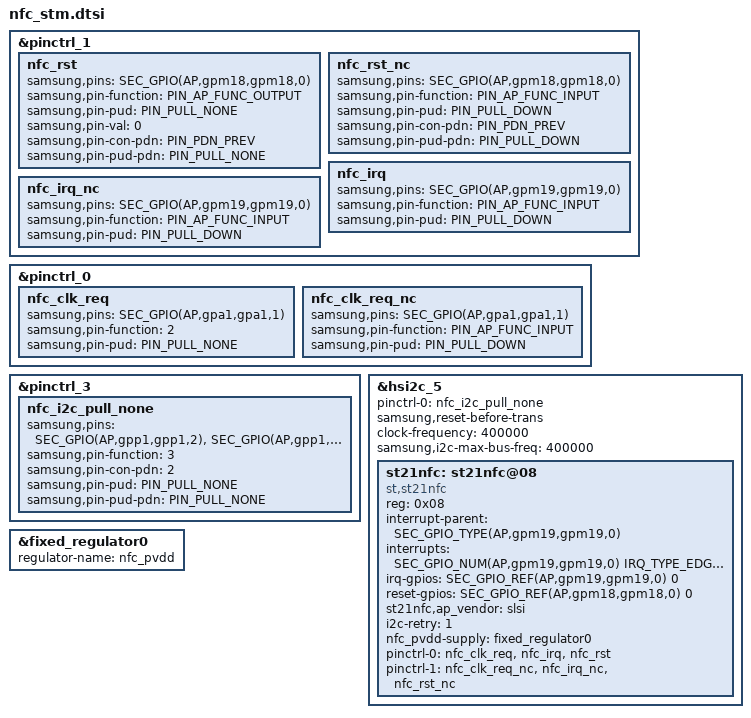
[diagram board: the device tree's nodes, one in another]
/*
 * This program is free software; you can redistribute it and/or modify
 * it under the terms of the GNU General Public License version 2 and
 * only version 2 as published by the Free Software Foundation.
 *
 * This program is distributed in the hope that it will be useful,
 * but WITHOUT ANY WARRANTY; without even the implied warranty of
 * MERCHANTABILITY or FITNESS FOR A PARTICULAR PURPOSE.  See the
 * GNU General Public License for more details.
 */

/* 
 * #define PIN_AP_FUNC_INPUT		0x0
 * #define PIN_AP_FUNC_OUTPUT		0x1
 * #define PIN_AP_FUNC_OUTPUT_HIGH	0x1
 * #define PIN_AP_FUNC_OUTPUT_LOW	0x1
 * #define PIN_AP_FUNC_INPUT_WAKEUP	0xf

 * arch/arm64/boot/dts/samsung/exynos_gpio_config_macros.dtsi
 * #define PIN_PDN_OUT0		0
 * #define PIN_PDN_OUT1		1
 * #define PIN_PDN_INPUT	2
 * #define PIN_PDN_PREV		3
 */

#ifndef PIN_PDN_PREV
#define PIN_PDN_PREV	3
#endif

&pinctrl_1 {
	nfc_rst: nfc_rst {
		samsung,pins = SEC_GPIO(AP,gpm18,gpm18,0);
		samsung,pin-function = <PIN_AP_FUNC_OUTPUT>;
		samsung,pin-pud = <PIN_PULL_NONE>;
		samsung,pin-val = <0>;
		samsung,pin-con-pdn = <PIN_PDN_PREV>;
		samsung,pin-pud-pdn = <PIN_PULL_NONE>;
	};
	nfc_rst_nc: nfc_rst_nc {
		samsung,pins = SEC_GPIO(AP,gpm18,gpm18,0);
		samsung,pin-function = <PIN_AP_FUNC_INPUT>;
		samsung,pin-pud = <PIN_PULL_DOWN>;
		samsung,pin-con-pdn = <PIN_PDN_PREV>;
		samsung,pin-pud-pdn = <PIN_PULL_DOWN>;
	};
};
&pinctrl_0 {
	nfc_clk_req: nfc_clk_req {
		samsung,pins = SEC_GPIO(AP,gpa1,gpa1,1);
		samsung,pin-function = <2>;
		samsung,pin-pud = <PIN_PULL_NONE>;
	};
	nfc_clk_req_nc: nfc_clk_req_nc {
		samsung,pins = SEC_GPIO(AP,gpa1,gpa1,1);
		samsung,pin-function = <PIN_AP_FUNC_INPUT>;
		samsung,pin-pud = <PIN_PULL_DOWN>;
	};
};

&pinctrl_1 {
	nfc_irq: nfc_irq {
		samsung,pins = SEC_GPIO(AP,gpm19,gpm19,0);
		samsung,pin-function = <PIN_AP_FUNC_INPUT>;
		samsung,pin-pud = <PIN_PULL_DOWN>;
	};
	nfc_irq_nc: nfc_irq_nc {
		samsung,pins = SEC_GPIO(AP,gpm19,gpm19,0);
		samsung,pin-function = <PIN_AP_FUNC_INPUT>;
		samsung,pin-pud = <PIN_PULL_DOWN>;
	};
};

#if 0
&${xclkout_parent} {
	nfc_xclkout: nfc_xclkout {
		samsung,pins = SEC_GPIO(${xclkout_gpio});
		samsung,pin-function = <2>;
		samsung,pin-pud = <PIN_PULL_NONE>;
	};
};
#endif

&pinctrl_3 {
	nfc_i2c_pull_none: nfc_i2c_pull_none {
		samsung,pins = SEC_GPIO(AP,gpp1,gpp1,2), SEC_GPIO(AP,gpp1,gpp1,3);
		samsung,pin-function = <3>;
		samsung,pin-con-pdn = <2>; /* PIN_PDN_INPUT */
		samsung,pin-pud = <PIN_PULL_NONE>;
		samsung,pin-pud-pdn = <PIN_PULL_NONE>;
	};

#if 0
	nfc_i2c_no_change: nfc_i2c_no_change {
		samsung,pins = SEC_GPIO(AP,gpp1,gpp1,2), SEC_GPIO(AP,gpp1,gpp1,3);
		samsung,pin-function = <3>;
		samsung,pin-con-pdn = <2>; /* PIN_PDN_INPUT */
	};
	nfc_i2c_pull_up: nfc_i2c_pull_up {
		samsung,pins = SEC_GPIO(AP,gpp1,gpp1,2), SEC_GPIO(AP,gpp1,gpp1,3);
		samsung,pin-function = <3>;
		samsung,pin-con-pdn = <2>; /* PIN_PDN_INPUT */
		samsung,pin-pud = <PIN_PULL_UP>;
		samsung,pin-pud-pdn = <PIN_PULL_UP>;
	};
#endif
};

#if 0
&${nfc_check_parent} {
	nfc_check: nfc_check {
		samsung,pins = SEC_GPIO(${nfc_check});
		samsung,pin-function = <PIN_AP_FUNC_INPUT>;
		samsung,pin-pud = <PIN_PULL_NONE>;
		samsung,pin-con-pdn = <PIN_PDN_PREV>;
		samsung,pin-pud-pdn = <PIN_PULL_NONE>;
	};
};
#endif

&hsi2c_5 {
	status = "ok";
	/delete-property/ pinctrl-names;
	/delete-property/ pinctrl-0;
#if 0
	pinctrl-names = "default", "i2c_pull_up";
	pinctrl-0 = <&nfc_i2c_no_change>;
	pinctrl-1 = <&nfc_i2c_pull_up>;
#else
	pinctrl-names = "default";
	pinctrl-0 = <&nfc_i2c_pull_none>;
#endif
	samsung,reset-before-trans;
	clock-frequency = <400000>; /* for HWI2C */
	samsung,i2c-max-bus-freq = <400000>; /* for Normal HW I2C */
	st21nfc: st21nfc@08 {
		compatible = "st,st21nfc";
		reg = <0x08>;
		interrupt-parent = <SEC_GPIO_TYPE(AP,gpm19,gpm19,0)>;
		interrupts = <SEC_GPIO_NUM(AP,gpm19,gpm19,0) IRQ_TYPE_EDGE_RISING
			SEC_GPIO_NUM(AP,gpm19,gpm19,0) 0>;
		irq-gpios = <SEC_GPIO_REF(AP,gpm19,gpm19,0) 0>;
		reset-gpios = <SEC_GPIO_REF(AP,gpm18,gpm18,0) 0>;
#if 0
		clkreq-gpios = <SEC_GPIO_REF(AP,gpa1,gpa1,1) 0>;
#endif
		st21nfc,ap_vendor = "slsi";
		i2c-retry = <1>;
#if 0
		st21nfc,nfc-det-gpio = <SEC_GPIO_REF(${nfc_check}) 0>;
#endif
#if 0
		st21nfc,late_pvdd_en;
#endif
#if 1
		nfc_pvdd-supply = <&fixed_regulator0>;
#endif

#if 0
		st21nfc,clk_req_wake;
#endif
#if 0
		st21nfc,irq_all_trigger;
#endif
#if 0
		st,clk_pinctrl;
		clocks = <&clock OSC_NFC>;
		clock-names = "nfc_ref_clk";
#endif

		pinctrl-names = "default", "nfc_nc";
/* default */
		pinctrl-0 = <&nfc_clk_req &nfc_irq &nfc_rst
#if 0
			&nfc_xclkout
#endif
#if 0
			&nfc_check
#endif
			>;
/* nfc_nc */
		pinctrl-1 = <&nfc_clk_req_nc &nfc_irq_nc &nfc_rst_nc>;
	};
};

&fixed_regulator0 {
	regulator-name = "nfc_pvdd";
};

#if 0

#if 0
&${ese_check_parent} {
	ese_check_default: ese_check_default {
		GPIO_CONFIG_PUD_DRV(${ese_check}, FUNC_INPUT, PULL_NONE, DRV_LV3);
		samsung,pin-con-pdn = <2>; /* PIN_PDN_INPUT */
		samsung,pin-pud-pdn = <PIN_PULL_NONE>;
	};
};
#endif

&${ese_ap_ese_rst_parent} {
	ese_ap_ese_rst_default: ese_ap_ese_rst_default {
		GPIO_CONFIG_PUD_DRV(${ese_ap_ese_rst}, FUNC_INPUT, PULL_NONE, DRV_LV3);
		samsung,pin-con-pdn = <2>; /* PIN_PDN_INPUT */
		samsung,pin-pud-pdn = <PIN_PULL_NONE>;
	};
};

&${ese_spi_parent} {
	ese_spi_bus_suspend: ese_spi_bus_suspend {
		samsung,pins = SEC_GPIO(${ese_spi_clk}), SEC_GPIO(${ese_spi_mosi}), SEC_GPIO(${ese_spi_miso});
		samsung,pin-function = <0>; /* INPUT */
		samsung,pin-pud = <PIN_PULL_DOWN>; /* DOWN */
		samsung,pin-drv = <PIN_AP_DRV_LV1>;
		samsung,pin-con-pdn = <2>; /* PIN_PDN_INPUT */
		samsung,pin-pud-pdn = <PIN_PULL_DOWN>;
	};

	ese_spi_cs_suspend: ese_spi_cs_suspend {
		samsung,pins = SEC_GPIO(${ese_spi_cs});
		samsung,pin-function = <1>; /* OUTPUT */
		samsung,pin-pud = <PIN_PULL_NONE>; /* NONE */
		samsung,pin-drv = <PIN_AP_DRV_LV1>;
		samsung,pin-val = <1>;
		samsung,pin-con-pdn = <1>; /*OUT1*/
		samsung,pin-pud-pdn = <PIN_PULL_NONE>;
	};

	ese_spi_bus: ese_spi_bus {
		samsung,pins = SEC_GPIO(${ese_spi_clk}), SEC_GPIO(${ese_spi_mosi}), SEC_GPIO(${ese_spi_miso});
		samsung,pin-function = <2>;
		samsung,pin-pud = <PIN_PULL_NONE>;
		samsung,pin-drv = <PIN_AP_DRV_LV1>;
	};

	ese_spi_cs: ese_spi_cs {
		samsung,pins = SEC_GPIO(${ese_spi_cs});
		samsung,pin-function = <1>;
		samsung,pin-pud = <PIN_PULL_NONE>;
		samsung,pin-drv = <PIN_AP_DRV_LV1>;
	};
};

&${ese_spi} {
	status = "ok";
	pinctrl-names = "default";
	pinctrl-0 = <&ese_spi_bus &ese_spi_cs>;

	st54spi: st54spi@0 {
		compatible = "st,st54spi";
		reg = <0>;
		spi-max-frequency = <1000000>;
		/*gpio-power_nreset-std = <SEC_GPIO_REF(${ese_power_reset}) 0>;*/
		st54spi,ap-ese-rst = <SEC_GPIO_REF(${ese_ap_ese_rst}) 0>;
		power_mode = "ST54J";
		st54spi,ap_vendor = "slsi";
#if 0
		ese-det-gpio = <SEC_GPIO_REF(${ese_check}) 0>;
#endif
		pinctrl-names = "default";
		pinctrl-0 = <&ese_ap_ese_rst_default
#if 0
			&ese_check_default
#endif
			>;

		gpio-controller;
		#gpio-cells = <2>;
		st54spi,cs-gpio = <SEC_GPIO_REF(${ese_spi_cs}) 0>;
		controller-data {
			samsung,spi-feedback-delay = <0>;
			samsung,spi-chip-select-mode = <0>;
		};
	};
};
#endif
